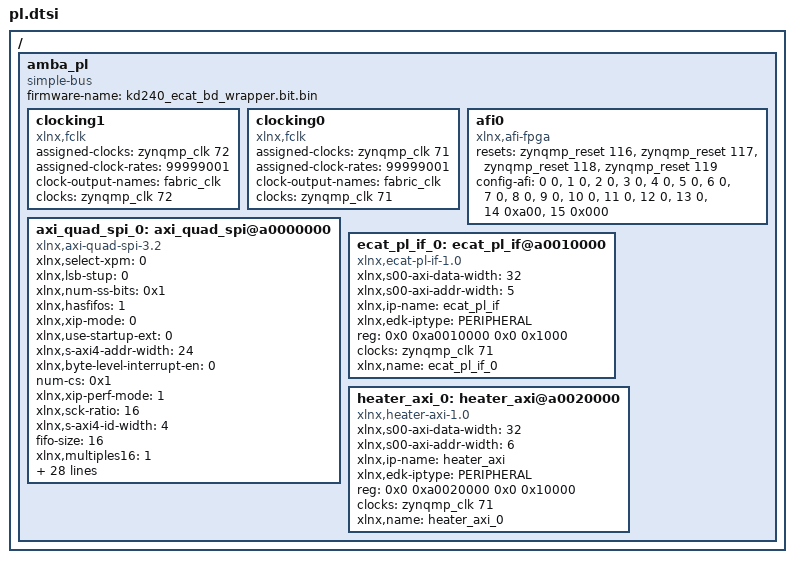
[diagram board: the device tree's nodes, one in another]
/ {
	amba_pl: amba_pl {
		ranges;
		compatible = "simple-bus";
		#address-cells = <2>;
		#size-cells = <2>;
		firmware-name = "kd240_ecat_bd_wrapper.bit.bin";
		clocking1: clocking1 {
			compatible = "xlnx,fclk";
			status = "okay";
			assigned-clocks = <&zynqmp_clk 72>;
			assigned-clock-rates = <99999001>;
			#clock-cells = <0>;
			clock-output-names = "fabric_clk";
			clocks = <&zynqmp_clk 72>;
		};
		clocking0: clocking0 {
			compatible = "xlnx,fclk";
			status = "okay";
			assigned-clocks = <&zynqmp_clk 71>;
			assigned-clock-rates = <99999001>;
			#clock-cells = <0>;
			clock-output-names = "fabric_clk";
			clocks = <&zynqmp_clk 71>;
		};
		afi0: afi0 {
			status = "okay";
			compatible = "xlnx,afi-fpga";
			resets = <&zynqmp_reset 116>, <&zynqmp_reset 117>, <&zynqmp_reset 118>, <&zynqmp_reset 119>;
			config-afi = < 0 0>, <1 0>, <2 0>, <3 0>, <4 0>, <5 0>, <6 0>, <7 0>, <8 0>, <9 0>, <10 0>, <11 0>, <12 0>, <13 0>, <14 0xa00>, <15 0x000>;
		};
		axi_quad_spi_0: axi_quad_spi@a0000000 {
			xlnx,select-xpm = <0>;
			compatible = "xlnx,axi-quad-spi-3.2" , "xlnx,xps-spi-2.00.a";
			xlnx,lsb-stup = <0>;
			xlnx,num-ss-bits = <0x1>;
			xlnx,hasfifos = <1>;
			xlnx,xip-mode = <0>;
			xlnx,use-startup-ext = <0>;
			xlnx,s-axi4-addr-width = <24>;
			xlnx,byte-level-interrupt-en = <0>;
			num-cs = <0x1>;
			xlnx,xip-perf-mode = <1>;
			xlnx,sck-ratio = <16>;
			xlnx,s-axi4-id-width = <4>;
			fifo-size = <16>;
			xlnx,multiples16 = <1>;
			xlnx,master-mode = <1>;
			xlnx,shared-startup = <0>;
			xlnx,ip-name = "axi_quad_spi";
			xlnx,qspi-board-interface = "Custom";
			reg = <0x0 0xa0000000 0x0 0x10000>;
			xlnx,dual-quad-mode = <0>;
			xlnx,new-seq-en = <1>;
			bits-per-word = <8>;
			clocks = <&zynqmp_clk 71>, <&zynqmp_clk 71>;
			xlnx,num-transfer-bits = <8>;
			xlnx,spi-memory = <1>;
			xlnx,s-axi4-data-width = <32>;
			xlnx,edk-iptype = "PERIPHERAL";
			xlnx,slaveonly = <0>;
			xlnx,use-startup-int = <0>;
			xlnx,use-startup = <0>;
			xlnx,type-of-axi4-interface = <0>;
			xlnx,async-clk = <0>;
			xlnx,spi-mode = <0>;
			xlnx,sck-ratio1 = <1>;
			status = "okay";
			xlnx,fifo-depth = <16>;
			clock-names = "ext_spi_clk" , "s_axi_aclk";
			xlnx,uc-family = <1>;
			xlnx,spi-mem-addr-bits = <24>;
			xlnx,axi-interface = <0>;
			xlnx,Axi4-address = <0>;
			xlnx,fifo-included = <1>;
			xlnx,sub-family = "zynquplus";
			xlnx,name = "axi_quad_spi_0";
		};
		ecat_pl_if_0: ecat_pl_if@a0010000 {
			xlnx,s00-axi-data-width = <32>;
			compatible = "xlnx,ecat-pl-if-1.0";
			status = "okay";
			clock-names = "s00_axi_aclk";
			xlnx,s00-axi-addr-width = <5>;
			xlnx,ip-name = "ecat_pl_if";
			xlnx,edk-iptype = "PERIPHERAL";
			reg = <0x0 0xa0010000 0x0 0x1000>;
			clocks = <&zynqmp_clk 71>;
			xlnx,name = "ecat_pl_if_0";
		};
		heater_axi_0: heater_axi@a0020000 {
			xlnx,s00-axi-data-width = <32>;
			compatible = "xlnx,heater-axi-1.0";
			status = "okay";
			clock-names = "s00_axi_aclk";
			xlnx,s00-axi-addr-width = <6>;
			xlnx,ip-name = "heater_axi";
			xlnx,edk-iptype = "PERIPHERAL";
			reg = <0x0 0xa0020000 0x0 0x10000>;
			clocks = <&zynqmp_clk 71>;
			xlnx,name = "heater_axi_0";
		};
	};
};
